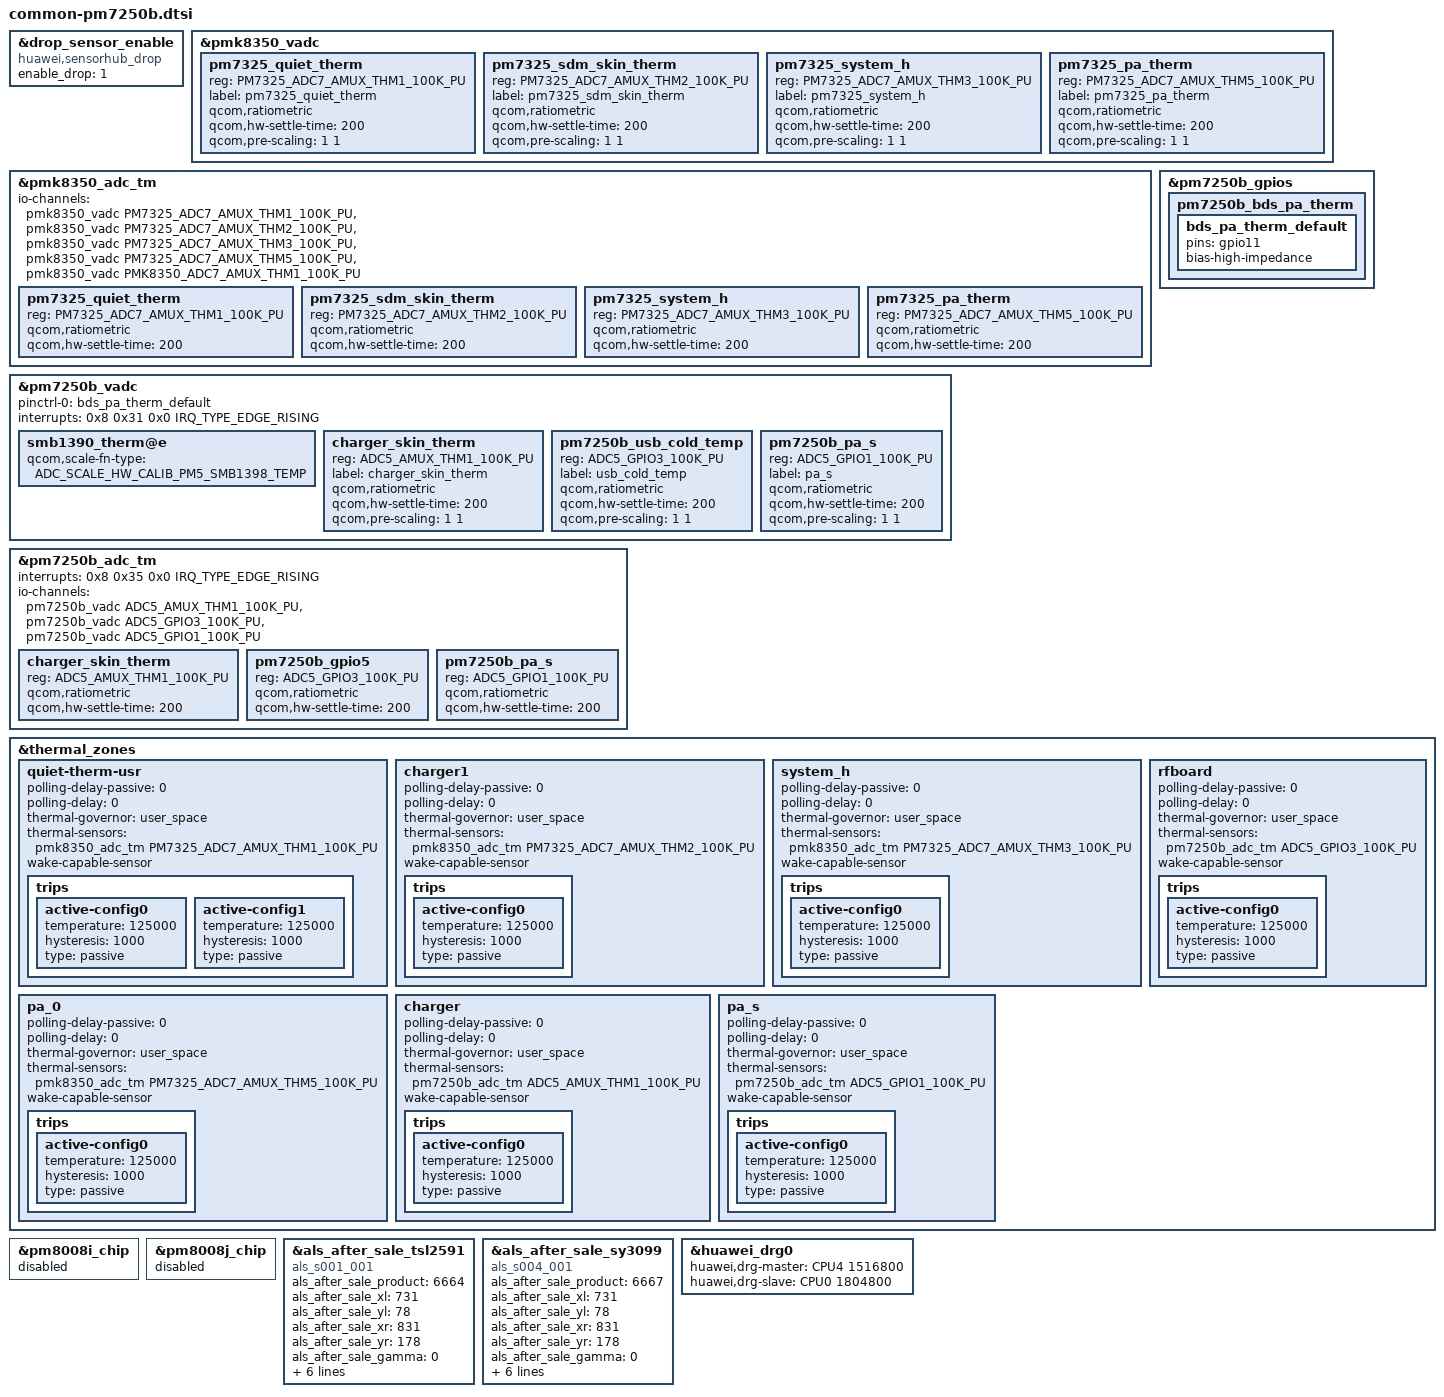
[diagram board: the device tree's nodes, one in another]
#include "../../../yupik-idp-pm7250b.dtsi"
#include <dt-bindings/pinctrl/qcom,pmic-gpio.h>
#include <dt-bindings/iio/qcom,spmi-adc7-pm7325.h>
#include "huawei_audio.dtsi"
#include "huawei_fac.dtsi"
#include "huawei_camera.dtsi"
#include "huawei-lcd.dtsi"
#include "huawei_tp.dtsi"
#include "huawei_charger.dtsi"
#include "huawei_fp.dtsi"
#include "huawei_usb.dtsi"
#include "huawei-sensor.dtsi"
#include "huawei_bsp.dtsi"

&drop_sensor_enable {
    compatible = "huawei,sensorhub_drop";
    enable_drop = "1";
};

&pmk8350_vadc {

	pm7325_quiet_therm {
		reg = <PM7325_ADC7_AMUX_THM1_100K_PU>;
		label = "pm7325_quiet_therm";
		qcom,ratiometric;
		qcom,hw-settle-time = <200>;
		qcom,pre-scaling = <1 1>;
	};

	pm7325_sdm_skin_therm {
		reg = <PM7325_ADC7_AMUX_THM2_100K_PU>;
		label = "pm7325_sdm_skin_therm";
		qcom,ratiometric;
		qcom,hw-settle-time = <200>;
		qcom,pre-scaling = <1 1>;
	};

	pm7325_system_h {
		reg = <PM7325_ADC7_AMUX_THM3_100K_PU>;
		label = "pm7325_system_h";
		qcom,ratiometric;
		qcom,hw-settle-time = <200>;
		qcom,pre-scaling = <1 1>;
	};

	pm7325_pa_therm {
		reg = <PM7325_ADC7_AMUX_THM5_100K_PU>;
		label = "pm7325_pa_therm";
		qcom,ratiometric;
		qcom,hw-settle-time = <200>;
		qcom,pre-scaling = <1 1>;
	};
};

&pmk8350_adc_tm {
	io-channels = <&pmk8350_vadc PM7325_ADC7_AMUX_THM1_100K_PU>,
			<&pmk8350_vadc PM7325_ADC7_AMUX_THM2_100K_PU>,
			<&pmk8350_vadc PM7325_ADC7_AMUX_THM3_100K_PU>,
			<&pmk8350_vadc PM7325_ADC7_AMUX_THM5_100K_PU>,
			<&pmk8350_vadc PMK8350_ADC7_AMUX_THM1_100K_PU>;

	pm7325_quiet_therm {
		reg = <PM7325_ADC7_AMUX_THM1_100K_PU>;
		qcom,ratiometric;
		qcom,hw-settle-time = <200>;
	};

	pm7325_sdm_skin_therm {
		reg = <PM7325_ADC7_AMUX_THM2_100K_PU>;
		qcom,ratiometric;
		qcom,hw-settle-time = <200>;
	};

	pm7325_system_h {
		reg = <PM7325_ADC7_AMUX_THM3_100K_PU>;
		qcom,ratiometric;
		qcom,hw-settle-time = <200>;
	};

	pm7325_pa_therm {
		reg = <PM7325_ADC7_AMUX_THM5_100K_PU>;
		qcom,ratiometric;
		qcom,hw-settle-time = <200>;
	};
};

&pm7250b_gpios {
	pm7250b_bds_pa_therm {
		bds_pa_therm_default: bds_pa_therm_default {
			pins = "gpio11";
			bias-high-impedance;
		};
	};
};

&pm7250b_vadc {
    pinctrl-names = "default";
	pinctrl-0 = <&bds_pa_therm_default>;
	
	interrupts = <0x8 0x31 0x0 IRQ_TYPE_EDGE_RISING>;

	smb1390_therm@e {
		qcom,scale-fn-type = <ADC_SCALE_HW_CALIB_PM5_SMB1398_TEMP>;
	};

	charger_skin_therm {
		reg = <ADC5_AMUX_THM1_100K_PU>;
		label = "charger_skin_therm";
		qcom,ratiometric;
		qcom,hw-settle-time = <200>;
		qcom,pre-scaling = <1 1>;
	};

	pm7250b_usb_cold_temp {
		reg = <ADC5_GPIO3_100K_PU>;
		label = "usb_cold_temp";
		qcom,ratiometric;
		qcom,hw-settle-time = <200>;
		qcom,pre-scaling = <1 1>;
	};
	
    pm7250b_pa_s {
		reg = <ADC5_GPIO1_100K_PU>;
		label = "pa_s";
		qcom,ratiometric;
		qcom,hw-settle-time = <200>;
		qcom,pre-scaling = <1 1>;
	};
};

&pm7250b_adc_tm {
	interrupts = <0x8 0x35 0x0 IRQ_TYPE_EDGE_RISING>;

	io-channels = <&pm7250b_vadc ADC5_AMUX_THM1_100K_PU>,
             <&pm7250b_vadc ADC5_GPIO3_100K_PU>,
             <&pm7250b_vadc ADC5_GPIO1_100K_PU>;

	charger_skin_therm {
		reg = <ADC5_AMUX_THM1_100K_PU>;
		qcom,ratiometric;
		qcom,hw-settle-time = <200>;
	};

	pm7250b_gpio5 {
		reg = <ADC5_GPIO3_100K_PU>;
		qcom,ratiometric;
		qcom,hw-settle-time = <200>;
	};
	
    pm7250b_pa_s {
		reg = <ADC5_GPIO1_100K_PU>;
		qcom,ratiometric;
		qcom,hw-settle-time = <200>;
	};
};

&thermal_zones {
	quiet-therm-usr {
		polling-delay-passive = <0>;
		polling-delay = <0>;
		thermal-governor = "user_space";
		thermal-sensors = <&pmk8350_adc_tm PM7325_ADC7_AMUX_THM1_100K_PU>;
		wake-capable-sensor;
		trips {
			active-config0 {
				temperature = <125000>;
				hysteresis = <1000>;
				type = "passive";
			};

			active-config1 {
				temperature = <125000>;
				hysteresis = <1000>;
				type = "passive";
			};
		};
	};

	charger1 {
		polling-delay-passive = <0>;
		polling-delay = <0>;
		thermal-governor = "user_space";
		thermal-sensors = <&pmk8350_adc_tm PM7325_ADC7_AMUX_THM2_100K_PU>;
		wake-capable-sensor;
		trips {
			active-config0 {
				temperature = <125000>;
				hysteresis = <1000>;
				type = "passive";
			};
		};
	};

	system_h {
		polling-delay-passive = <0>;
		polling-delay = <0>;
		thermal-governor = "user_space";
		thermal-sensors = <&pmk8350_adc_tm PM7325_ADC7_AMUX_THM3_100K_PU>;
		wake-capable-sensor;
		trips {
			active-config0 {
				temperature = <125000>;
				hysteresis = <1000>;
				type = "passive";
			};
		};
	};

	pa_0 {
		polling-delay-passive = <0>;
		polling-delay = <0>;
		thermal-governor = "user_space";
		thermal-sensors = <&pmk8350_adc_tm PM7325_ADC7_AMUX_THM5_100K_PU>;
		wake-capable-sensor;
		trips {
			active-config0 {
				temperature = <125000>;
				hysteresis = <1000>;
				type = "passive";
			};
		};
	};


	charger {
		polling-delay-passive = <0>;
		polling-delay = <0>;
		thermal-governor = "user_space";
		thermal-sensors = <&pm7250b_adc_tm ADC5_AMUX_THM1_100K_PU>;
		wake-capable-sensor;
		trips {
			active-config0 {
				temperature = <125000>;
				hysteresis = <1000>;
				type = "passive";
			};
		};
	};

	rfboard {
		polling-delay-passive = <0>;
		polling-delay = <0>;
		thermal-governor = "user_space";
		thermal-sensors = <&pm7250b_adc_tm ADC5_GPIO3_100K_PU>;
		wake-capable-sensor;
		trips {
			active-config0 {
				temperature = <125000>;
				hysteresis = <1000>;
				type = "passive";
			};
		};
	};
	
	pa_s {
		polling-delay-passive = <0>;
		polling-delay = <0>;
		thermal-governor = "user_space";
		thermal-sensors = <&pm7250b_adc_tm ADC5_GPIO1_100K_PU>;
		wake-capable-sensor;
		trips {
			active-config0 {
				temperature = <125000>;
				hysteresis = <1000>;
				type = "passive";
			};
		};
	};
};

&pm8008i_chip {
	status = "disabled";
};

&pm8008j_chip {
	status = "disabled";
};

&als_after_sale_tsl2591 {
    compatible = "als_s001_001";
    als_after_sale_product = <6664>;
    als_after_sale_xl = <731>;
    als_after_sale_yl = <78>;
    als_after_sale_xr = <831>;
    als_after_sale_yr = <178>;
    als_after_sale_gamma = <0>;
    190_20f_1 = "781,128,1,1,220,192,159,127,102,74,56,31,4";
    310_106_1 = "781,128,4,1,220,192,159,127,102,74,56,31,4";
    default = "781,128,4,1,220,192,159,127,102,74,56,31,4";
};

&als_after_sale_sy3099 {
    compatible = "als_s004_001";
    als_after_sale_product = <6667>;
    als_after_sale_xl = <731>;
    als_after_sale_yl = <78>;
    als_after_sale_xr = <831>;
    als_after_sale_yr = <178>;
    als_after_sale_gamma = <0>;
    190_20f_1 = "781,128,1,1,220,192,159,127,102,74,56,31,4";
    310_106_1 = "781,128,4,1,220,192,159,127,102,74,56,31,4";
    default = "781,128,4,1,220,192,159,127,102,74,56,31,4";
};

&huawei_drg0 {
	huawei,drg-master = <&CPU4 1516800>;
	huawei,drg-slave = <&CPU0 1804800>;
};
